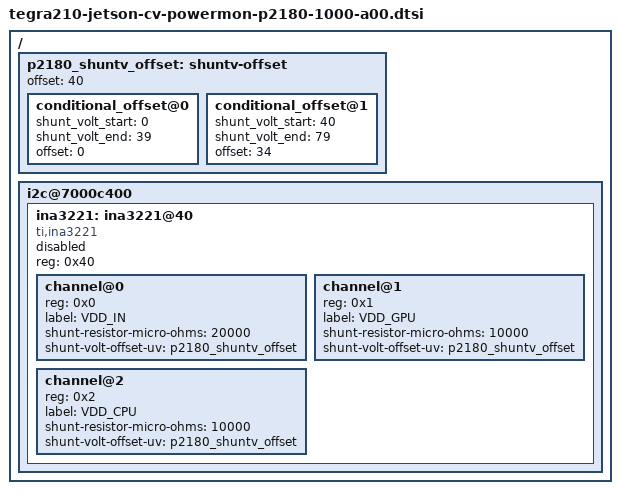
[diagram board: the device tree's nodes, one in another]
/*
 * Copyright (c) 2015, NVIDIA CORPORATION.  All rights reserved.
 *
 * This program is free software; you can redistribute it and/or modify
 * it under the terms of the GNU General Public License as published by
 * the Free Software Foundation; version 2 of the License.
 *
 * This program is distributed in the hope that it will be useful, but WITHOUT
 * ANY WARRANTY; without even the implied warranty of MERCHANTABILITY or
 * FITNESS FOR A PARTICULAR PURPOSE.  See the GNU General Public License for
 * more details.
 *
 */

/ {
	p2180_shuntv_offset: shuntv-offset {
		offset = <40>;
		conditional_offset@0 {
			shunt_volt_start = <0>;
			shunt_volt_end = <39>;
			offset = <0>;
		};
		conditional_offset@1 {
			shunt_volt_start = <40>;
			shunt_volt_end = <79>;
			offset = <34>;
		};
	};

	i2c@7000c400 {
		ina3221: ina3221@40 {
			compatible = "ti,ina3221";
			reg = <0x40>;
			#io-channel-cells = <1>;
			#address-cells = <1>;
			#size-cells = <0>;
			status = "disabled";

			channel@0 {
				reg = <0x0>;
				label = "VDD_IN";
				shunt-resistor-micro-ohms = <20000>;
				shunt-volt-offset-uv = <&p2180_shuntv_offset>;
			};

			channel@1 {
				reg = <0x1>;
				label = "VDD_GPU";
				shunt-resistor-micro-ohms = <10000>;
				shunt-volt-offset-uv = <&p2180_shuntv_offset>;
			};

			channel@2 {
				reg = <0x2>;
				label = "VDD_CPU";
				shunt-resistor-micro-ohms = <10000>;
				shunt-volt-offset-uv = <&p2180_shuntv_offset>;
			};
		};
	};
};
